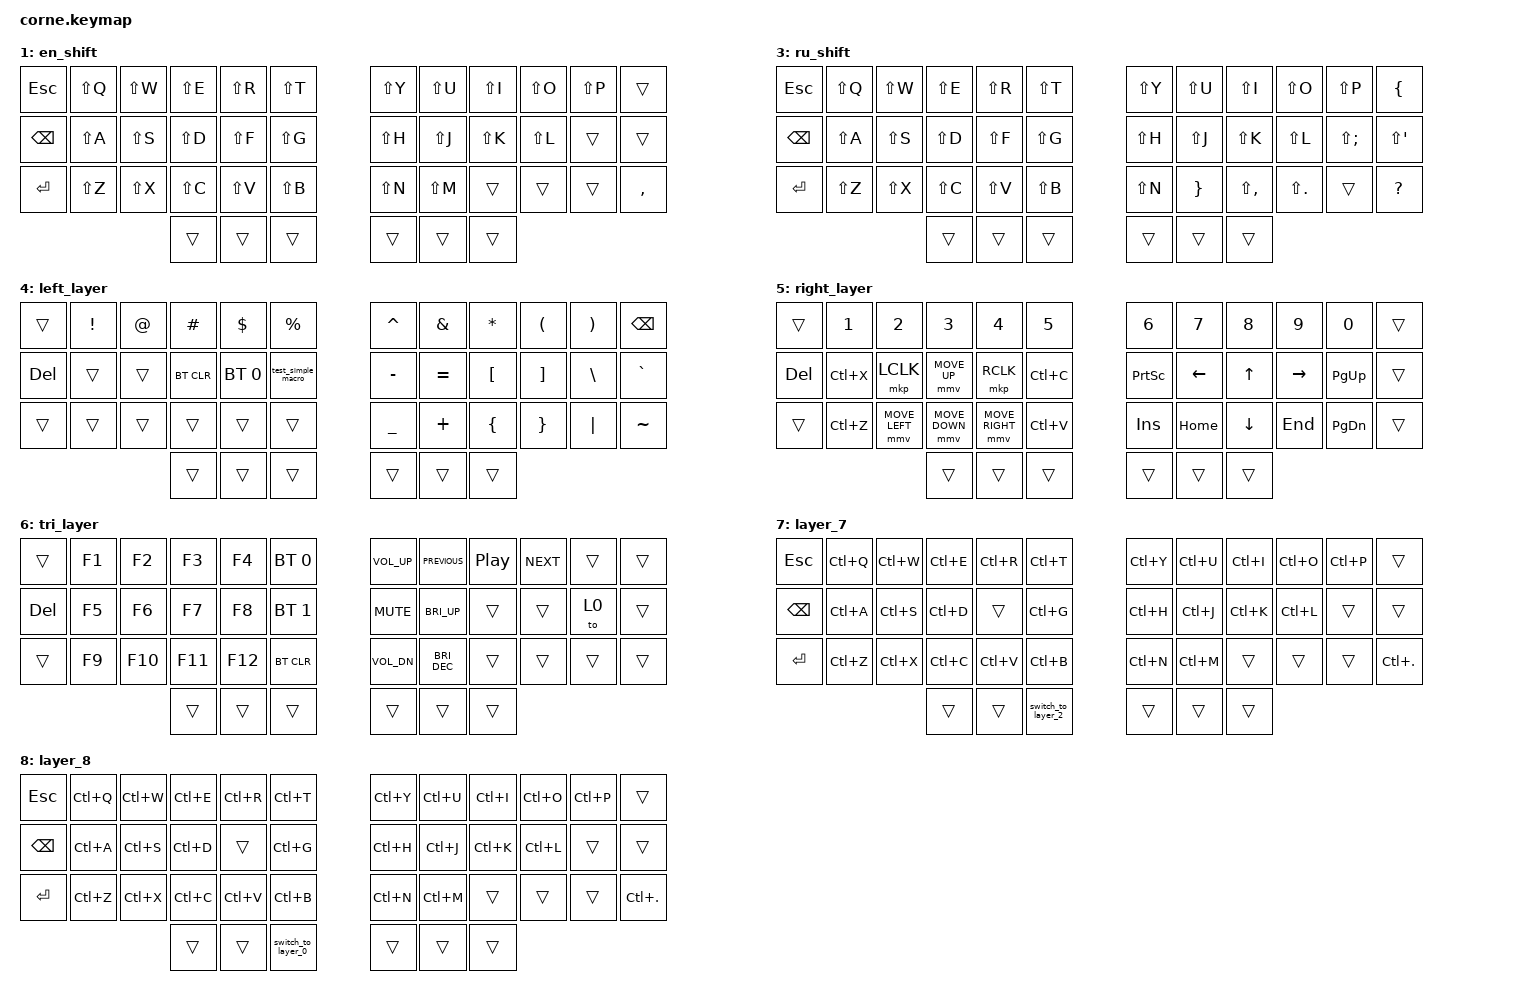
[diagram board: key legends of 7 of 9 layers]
/*
 * Copyright (c) 2020 The ZMK Contributors
 *
 * SPDX-License-Identifier: MIT
 */

#include <behaviors.dtsi>
#include <dt-bindings/zmk/bt.h>
#include <dt-bindings/zmk/keys.h>
#include <dt-bindings/zmk/pointing.h>

// Home row mods macro
#define HRML(k2,k3,k4) &ht LALT k2  &ht LCTRL k3  &ht LGUI k4
#define HRMR(k1,k2,k3) &ht RGUI k1  &ht RCTRL k2  &ht RALT k3
#define LEN7(k2,k3,k4) &ht LALT k2  &ht LGUI k3  &lt 7 k4
#define REN(k1,k2,k3) &ht RCTRL k1  &ht RGUI k2  &ht RALT k3
#define LRU8(k2,k3,k4) &ht LALT k2  &ht LGUI k3  &lt 8 k4
#define RRU(k1,k2,k3) &ht RCTRL k1  &ht RGUI k2  &ht RALT k3
//#define WHRML(k2,k3,k4) &ht LALT k2  &ht LGUI k3  &ht LCTRL k4
//#define WHRMR(k1,k2,k3) &ht RCTRL k1  &ht RGUI k2  &ht RALT k3


//#define HRML(k2, k3, k4, _layer) &ht LALT k2  &hml LCTRL k3 _layer  &ht LGUI k4
//#define HRMR(k1, k2, k3, _layer) &ht RGUI k1  &hml RCTRL k2 _layer  &ht RALT k3
//#define WHRML(k2,k3,k4,_layer) &ht LALT k2  &ht LGUI k3  &hml LCTRL k4 _layer
//#define WHRMR(k1,k2,k3,_layer) &hml RCTRL k1 _layer  &ht RGUI k2  &ht RALT k3
//WHRML(S, D, F, 7)
//WHRMR(J, K, L, 8)



/ {
    behaviors {
        ht: hold_tap {
            label = "hold_tap";
            compatible = "zmk,behavior-hold-tap";
            #binding-cells = <2>; // 2 аргумента: (модификатор, клавиша)
            flavor = "tap-preferred";
            tapping-term-ms = <220>;
            quick-tap-ms = <150>;
            global-quick-tap;
            bindings = <&kp>, <&kp>;
        };

        hml: hold_mod_layer {
            compatible = "zmk,behavior-hold-mod-layer";
            #binding-cells = <3>; // 3 аргумента: (модификатор, клавиша, слой)
            label = "HOLD_MOD_LAYER";
            flavor = "tap-preferred";
            tapping-term-ms = <220>; // Синхронизировано с ht
            quick-tap-ms = <150>;
            global-quick-tap;
            bindings = <&kp>, <&kp>;
        };
    };

    macros {
        switch_to_layer_0: switch_to_layer_0_macro {
            compatible = "zmk,behavior-macro";
            label = "SWITCH_TO_LAYER_0";
            #binding-cells = <0>;
            bindings =
                <&macro_press>,
                <&kp LSHFT>,
                <&macro_press>,
                <&kp LCTRL>,
                <&macro_wait_time 10>,
                <&macro_release>,
                <&kp LCTRL>,
                <&macro_release>,
                <&kp LSHFT>,
                <&macro_tap>,
                <&to 0>;
        };

        switch_to_layer_2: switch_to_layer_2_macro {
            compatible = "zmk,behavior-macro";
            label = "SWITCH_TO_LAYER_2";
            #binding-cells = <0>;
            bindings =
                <&macro_press>,
                <&kp LSHFT>,
                <&macro_press>,
                <&kp LCTRL>,
                <&macro_wait_time 10>,
                <&macro_release>,
                <&kp LCTRL>,
                <&macro_release>,
                <&kp LSHFT>,
                <&macro_tap>,
                <&to 2>;
        };

        test_simple_macro: test_simple_macro {
            compatible = "zmk,behavior-macro";
            #binding-cells = <0>;
                bindings =
                    <&macro_press>,
                    <&kp LSHFT>,
                    <&macro_tap>, 
                    <&kp A>,
                    <&kp B>, 
                    <&kp C>, // Просто отправляет Shift + 'A'
                    <&macro_wait_time 10>,
                    <&macro_release>,
                    <&kp LSHFT>;   
        };
    };

    conditional_layers {
        compatible = "zmk,conditional-layers";

        tri_layer_condition {
            if-layers = <4 5>;
            then-layer = <6>;
        };
    };

    keymap {
        compatible = "zmk,keymap";

        default_layer {
            // -----------------------------------------------------------------------------------------
            // |  TAB |  Q  |  W  |  E  |  R  |  T  |   |  Y  |  U   |  I  |  O  |  P  | BSPC |
            // | CTRL |  A  |  S  |  D  |  F  |  G  |   |  H  |  J   |  K  |  L  |  ;  |  '   |
            // | SHFT |  Z  |  X  |  C  |  V  |  B  |   |  N  |  M   |  ,  |  .  |  /  | ESC  |
            //                    | GUI | LWR | SPC |   | ENT | RSE  | ALT |
            //     

            bindings = <
&kp ESCAPE     &kp Q      &kp W      &kp E       &kp R     &kp T             &kp Y      &kp U      &kp I      &kp O      &kp P      &trans
&kp BACKSPACE  &kp A             LEN7(S, D, F)            &kp G             &kp H               REN(J, K, L)          &trans     &trans
&kp ENTER      &kp Z      &kp X      &kp C       &kp V     &kp B             &kp N      &kp M      &trans     &trans     &trans     &kp DOT
                                     &kp TAB     &mo 4     &mo 1             &kp SPACE  &mo 5      &kp TAB
            >;
        };

        en_shift {
            bindings = <
&kp ESCAPE     &kp LS(Q)  &kp LS(W)  &kp LS(E)  &kp LS(R)  &kp LS(T)        &kp LS(Y)  &kp LS(U)  &kp LS(I)  &kp LS(O)  &kp LS(P)   &trans
&kp BACKSPACE  &kp LS(A)  &kp LS(S)  &kp LS(D)  &kp LS(F)  &kp LS(G)        &kp LS(H)  &kp LS(J)  &kp LS(K)  &kp LS(L)  &trans      &trans
&kp ENTER      &kp LS(Z)  &kp LS(X)  &kp LS(C)  &kp LS(V)  &kp LS(B)        &kp LS(N)  &kp LS(M)  &trans     &trans     &trans      &kp COMMA
                                              &trans  &trans  &trans        &trans &trans  &trans
            >;
        };

        ru_layer {
            bindings = <
&kp ESCAPE     &kp Q      &kp W      &kp E       &kp R     &kp T             &kp Y      &kp U      &kp I      &kp O      &kp P      &kp LBKT
&kp BACKSPACE  &kp A             LRU8(S, D, F)             &kp G             &kp H                RRU(J, K, L)           &kp SEMI   &kp SQT
&kp ENTER      &kp Z      &kp X      &kp C       &kp V     &kp B             &kp N      &kp M      &kp COMMA  &kp DOT    &trans     &kp FSLH
                                        &trans  &trans     &mo 3             &trans     &trans     &trans
            >;
        };

        ru_shift {
            bindings = <
&kp ESCAPE     &kp LS(Q)  &kp LS(W)  &kp LS(E)  &kp LS(R)  &kp LS(T)        &kp LS(Y)  &kp LS(U)  &kp LS(I)  &kp LS(O)  &kp LS(P)     &kp LBRC
&kp BACKSPACE  &kp LS(A)  &kp LS(S)  &kp LS(D)  &kp LS(F)  &kp LS(G)        &kp LS(H)  &kp LS(J)  &kp LS(K)  &kp LS(L)  &kp LS(SEMI)  &kp LS(SQT)
&kp ENTER      &kp LS(Z)  &kp LS(X)  &kp LS(C)  &kp LS(V)  &kp LS(B)        &kp LS(N)  &kp RBRC   &kp LS(COMMA)  &kp LS(DOT)  &trans  &kp QMARK
                                              &trans  &trans  &trans        &trans &trans  &trans
            >;
        };

        left_layer {
            bindings = <
&trans   &kp EXCL  &kp AT  &kp HASH  &kp DLLR  &kp PRCNT    &kp CARET  &kp AMPS   &kp ASTRK  &kp LPAR  &kp RPAR  &kp BSPC
&kp DEL  &trans    &trans  &bt BT_CLR  &bt BT_SEL 0   &test_simple_macro       &kp MINUS  &kp EQUAL  &kp LBKT   &kp RBKT  &kp BSLH  &kp GRAVE
&trans   &trans    &trans  &trans    &trans    &trans       &kp UNDER  &kp PLUS   &kp LBRC   &kp RBRC  &kp PIPE  &kp TILDE
                           &trans    &trans    &trans       &trans     &trans     &trans
            >;
        };

        right_layer {
            bindings = <
&trans   &kp N1     &kp N2          &kp N3          &kp N4           &kp N5       &kp N6           &kp N7    &kp N8    &kp N9     &kp N0     &trans
&kp DEL  &kp LC(X)  &mkp LCLK       &mmv MOVE_UP    &mkp RCLK        &kp LC(C)    &kp PRINTSCREEN  &kp LEFT  &kp UP    &kp RIGHT  &kp PG_UP  &trans
&trans   &kp LC(Z)  &mmv MOVE_LEFT  &mmv MOVE_DOWN  &mmv MOVE_RIGHT  &kp LC(V)    &kp INSERT       &kp HOME  &kp DOWN  &kp END    &kp PG_DN  &trans
                                    &trans          &trans           &trans       &trans           &trans    &trans
            >;
        };

        tri_layer {
            bindings = <
&trans  &kp F1  &kp F2   &kp F3   &kp F4   &bt BT_SEL 0    &kp C_VOL_UP  &kp C_PREVIOUS  &kp C_PLAY_PAUSE  &kp C_NEXT  &trans  &trans
&kp DEL &kp F5  &kp F6   &kp F7   &kp F8   &bt BT_SEL 1    &kp C_MUTE    &kp C_BRI_UP    &trans            &trans      &to 0   &trans
&trans  &kp F9  &kp F10  &kp F11  &kp F12  &bt BT_CLR      &kp C_VOL_DN  &kp C_BRI_DEC   &trans            &trans      &trans  &trans
                             &trans   &trans   &trans      &trans        &trans          &trans
            >;
        };

        layer_7 {
            bindings = <
&kp ESCAPE     &kp LC(Q)  &kp LC(W)  &kp LC(E)  &kp LC(R)  &kp LC(T)      &kp LC(Y)  &kp LC(U)  &kp LC(I)  &kp LC(O)  &kp LC(P)  &trans
&kp BACKSPACE  &kp LC(A)  &kp LC(S)  &kp LC(D)  &trans     &kp LC(G)      &kp LC(H)  &kp LC(J)  &kp LC(K)  &kp LC(L)  &trans     &trans
&kp ENTER      &kp LC(Z)  &kp LC(X)  &kp LC(C)  &kp LC(V)  &kp LC(B)      &kp LC(N)  &kp LC(M)  &trans     &trans     &trans     &kp LC(DOT)
                                  &trans  &trans  &switch_to_layer_2      &trans  &trans  &trans
            >;
        };

        layer_8 {
            bindings = <
&kp ESCAPE     &kp LC(Q)  &kp LC(W)  &kp LC(E)  &kp LC(R)  &kp LC(T)      &kp LC(Y)  &kp LC(U)  &kp LC(I)  &kp LC(O)  &kp LC(P)  &trans
&kp BACKSPACE  &kp LC(A)  &kp LC(S)  &kp LC(D)  &trans     &kp LC(G)      &kp LC(H)  &kp LC(J)  &kp LC(K)  &kp LC(L)  &trans     &trans
&kp ENTER      &kp LC(Z)  &kp LC(X)  &kp LC(C)  &kp LC(V)  &kp LC(B)      &kp LC(N)  &kp LC(M)  &trans     &trans     &trans     &kp LC(DOT)
                                  &trans  &trans  &switch_to_layer_0      &trans  &trans  &trans
            >;
        };
    };
};
